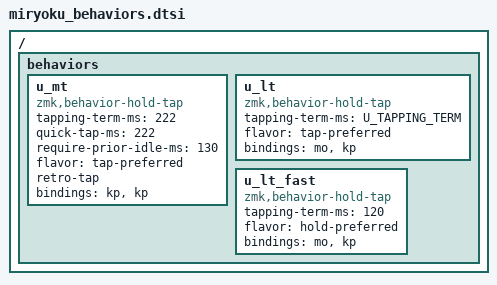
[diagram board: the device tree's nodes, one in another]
// Copyright 2022 Manna Harbour
// https://github.com/manna-harbour/miryoku

/ {
  behaviors {
    u_mt: u_mt {
      compatible = "zmk,behavior-hold-tap";
      #binding-cells = <2>;
      tapping-term-ms = <222>;
      quick-tap-ms = <222>;
      require-prior-idle-ms = <130>;
      flavor = "tap-preferred";
      retro-tap;
      bindings = <&kp>, <&kp>;
    };
    u_lt: u_lt {
      compatible = "zmk,behavior-hold-tap";
      #binding-cells = <2>;
      tapping-term-ms = <U_TAPPING_TERM>;
      flavor = "tap-preferred";
      bindings = <&mo>, <&kp>;
    };
    u_lt_fast: u_lt_fast {
      compatible = "zmk,behavior-hold-tap";
      #binding-cells = <2>;
      tapping-term-ms = <120>;
      flavor = "hold-preferred";
      bindings = <&mo>, <&kp>;
    };
  };
};
